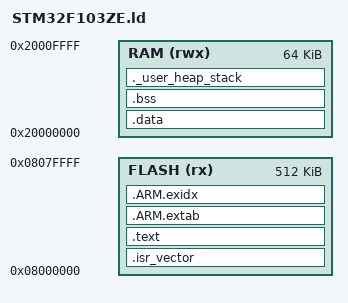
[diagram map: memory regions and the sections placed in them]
/* Linker script for STM32F103ZE */

MEMORY
{
    FLASH (rx)  : ORIGIN = 0x08000000, LENGTH = 512K
    RAM   (rwx) : ORIGIN = 0x20000000, LENGTH = 64K
}

_estack = ORIGIN(RAM) + LENGTH(RAM);

/* Sections */
SECTIONS
{
    /* Vector table and code */
    .isr_vector :
    {
        KEEP(*(.isr_vector))
    } > FLASH

    .text :
    {
        *(.text*)
        *(.rodata*)
        *(.glue_7)
        *(.glue_7t)
        *(.eh_frame)
    } > FLASH

    .ARM.extab :
    {
        *(.ARM.extab*)
    } > FLASH

    .ARM.exidx :
    {
        *(.ARM.exidx*)
    } > FLASH

    /* Initialized data in RAM, load from FLASH */
    .data : AT (ADDR(.text) + SIZEOF(.text))
    {
        _sdata = .;
        *(.data*)
        _edata = .;
    } > RAM

    /* Zero-initialized data */
    .bss :
    {
        _sbss = .;
        *(.bss*)
        *(COMMON)
        _ebss = .;
    } > RAM

    /* Heap and stack */
    ._user_heap_stack :
    {
        . = ALIGN(8);
        PROVIDE(end = .);
        PROVIDE(_end = .);
    } > RAM
}
